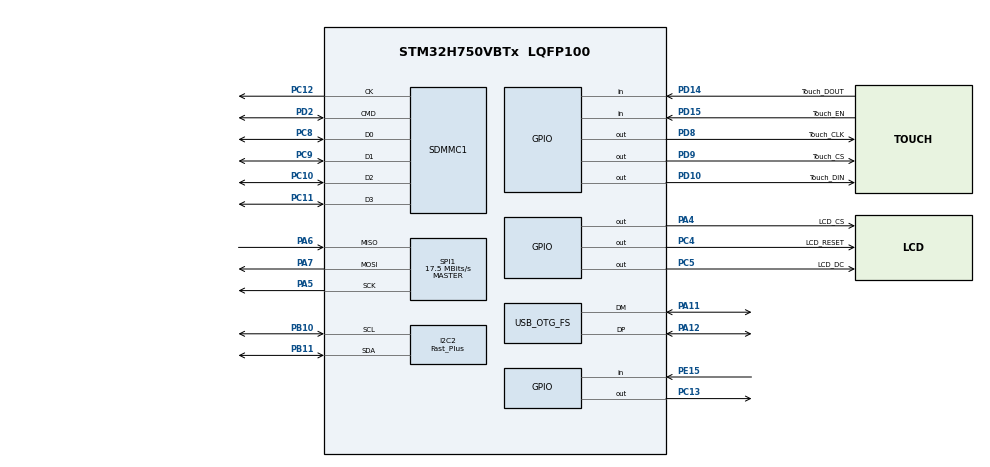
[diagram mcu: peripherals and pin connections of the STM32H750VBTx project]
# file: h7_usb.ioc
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FATFS.BSP.number=1
FATFS0.BSP.STBoard=false
FATFS0.BSP.api=Unknown
FATFS0.BSP.i2caddr=0
FATFS0.BSP.instance=PE15
FATFS0.BSP.ip=GPIO
FATFS0.BSP.mode=Input
FATFS0.BSP.name=Detect_SDIO
FATFS0.BSP.solution=PE15
I2C2.I2C_Speed_Mode=I2C_Fast_Plus
I2C2.Speed=1000
I2C2.Timing=0x0050174F
Mcu.Family=STM32H7
Mcu.Name=STM32H750VBTx
Mcu.Package=LQFP100
NVIC.OTG_FS_IRQn=true\:0\:0\:false\:false\:true\:false\:true
NVIC.PriorityGroup=NVIC_PRIORITYGROUP_4
NVIC.TIM2_IRQn=true\:0\:0\:false\:false\:true\:true\:true
PA10.Signal=USART1_RX
PA11.Mode=Device_Only
PA11.Signal=USB_OTG_FS_DM
PA12.Mode=Device_Only
PA12.Signal=USB_OTG_FS_DP
PA13\ (JTMS/SWDIO).Mode=JTAG_4_pins
PA13\ (JTMS/SWDIO).Signal=DEBUG_JTMS-SWDIO
PA14\ (JTCK/SWCLK).Mode=JTAG_4_pins
PA14\ (JTCK/SWCLK).Signal=DEBUG_JTCK-SWCLK
PA15\ (JTDI).Mode=JTAG_4_pins
PA15\ (JTDI).Signal=DEBUG_JTDI
PA4.GPIO_Label=LCD_CS
PA4.GPIO_Speed=GPIO_SPEED_FREQ_VERY_HIGH
PA4.Signal=GPIO_Output
PA5.Mode=Full_Duplex_Master
PA5.Signal=SPI1_SCK
PA6.Mode=Full_Duplex_Master
PA6.Signal=SPI1_MISO
PA7.Mode=Full_Duplex_Master
PA7.Signal=SPI1_MOSI
PA9.Signal=USART1_TX
PB10.Mode=I2C
PB10.Signal=I2C2_SCL
PB11.Mode=I2C
PB11.Signal=I2C2_SDA
PB3\ (JTDO/TRACESWO).Mode=JTAG_4_pins
PB3\ (JTDO/TRACESWO).Signal=DEBUG_JTDO-SWO
PC10.Mode=SD_4_bits_Wide_bus
PC10.Signal=SDMMC1_D2
PC11.Mode=SD_4_bits_Wide_bus
PC11.Signal=SDMMC1_D3
PC12.Mode=SD_4_bits_Wide_bus
PC12.Signal=SDMMC1_CK
PC13.Signal=GPIO_Output
PC4.GPIO_Label=LCD_RESET
PC4.GPIO_Speed=GPIO_SPEED_FREQ_VERY_HIGH
PC4.Signal=GPIO_Output
PC5.GPIO_Label=LCD_DC
PC5.GPIO_Speed=GPIO_SPEED_FREQ_VERY_HIGH
PC5.Signal=GPIO_Output
PC8.Mode=SD_4_bits_Wide_bus
PC8.Signal=SDMMC1_D0
PC9.Mode=SD_4_bits_Wide_bus
PC9.Signal=SDMMC1_D1
PD10.GPIO_Label=Touch_DIN
PD10.GPIO_Speed=GPIO_SPEED_FREQ_HIGH
PD10.Signal=GPIO_Output
PD14.GPIO_Label=Touch_DOUT
PD14.GPIO_PuPd=GPIO_PULLUP
PD14.Signal=GPIO_Input
PD15.GPIO_Label=Touch_EN
PD15.GPIO_PuPd=GPIO_PULLUP
PD15.Signal=GPIO_Input
PD2.Mode=SD_4_bits_Wide_bus
PD2.Signal=SDMMC1_CMD
PD8.GPIO_Label=Touch_CLK
PD8.GPIO_Speed=GPIO_SPEED_FREQ_HIGH
PD8.Signal=GPIO_Output
PD9.GPIO_Label=Touch_CS
PD9.GPIO_Speed=GPIO_SPEED_FREQ_HIGH
PD9.Signal=GPIO_Output
PE15.GPIO_PuPd=GPIO_PULLDOWN
PE15.Signal=GPIO_Input
PH0-OSC_IN\ (PH0).Mode=HSE-External-Oscillator
PH0-OSC_IN\ (PH0).Signal=RCC_OSC_IN
PH1-OSC_OUT\ (PH1).Mode=HSE-External-Oscillator
PH1-OSC_OUT\ (PH1).Signal=RCC_OSC_OUT
ProjectManager.HeapSize=0x2200
ProjectManager.StackSize=0x2400
ProjectManager.TargetToolchain=MDK-ARM V5
RCC.ADCFreq_Value=35000000
RCC.APB1Freq_Value=120000000
RCC.APB2Freq_Value=120000000
RCC.APB3Freq_Value=120000000
RCC.APB4Freq_Value=120000000
RCC.CortexFreq_Value=480000000
RCC.D1PPRE=RCC_APB3_DIV2
RCC.D2PPRE1=RCC_APB1_DIV2
RCC.D2PPRE2=RCC_APB2_DIV2
RCC.D3PPRE=RCC_APB4_DIV2
RCC.DIVM1=5
RCC.DIVM2=25
RCC.DIVM3=25
RCC.DIVN1=192
RCC.DIVN2=210
RCC.DIVN3=192
RCC.DIVP2=6
RCC.DIVQ3=4
RCC.DIVR2=5
RCC.DIVR3=6
RCC.HCLKFreq_Value=240000000
RCC.HPRE=RCC_HCLK_DIV2
RCC.HSE_VALUE=25000000
RCC.SDMMC1CLockSelection=RCC_SDMMCCLKSOURCE_PLL2
RCC.SPI123CLockSelection=RCC_SPI123CLKSOURCE_PLL2
RCC.SYSCLKFreq_VALUE=480000000
RCC.SYSCLKSource=RCC_SYSCLKSOURCE_PLLCLK
RCC.USBCLockSelection=RCC_USBCLKSOURCE_PLL3
RCC.USBFreq_Value=48000000
SPI1.CalculateBaudRate=17.5 MBits/s
SPI1.DataSize=SPI_DATASIZE_8BIT
SPI1.Direction=SPI_DIRECTION_2LINES
SPI1.Mode=SPI_MODE_MASTER
SPI1.VirtualType=VM_MASTER
TIM2.Period=1000-1
TIM2.Prescaler=240-1
TIM6.AutoReloadPreload=TIM_AUTORELOAD_PRELOAD_ENABLE
TIM6.Period=65535
TIM6.Prescaler=240-1
USB_DEVICE.CLASS_NAME_FS=CDC
USB_DEVICE.VirtualMode-CDC_FS=Cdc
USB_DEVICE.VirtualModeFS=Cdc_FS
USB_OTG_FS.VirtualMode=Device_Only
VP_FATFS_VS_SDIO.Mode=SDIO
VP_RNG_VS_RNG.Mode=RNG_Activate
VP_TIM2_VS_ClockSourceINT.Mode=Internal
VP_TIM6_VS_ClockSourceINT.Mode=Enable_Timer
VP_USB_DEVICE_VS_USB_DEVICE_CDC_FS.Mode=CDC_FS
board=custom

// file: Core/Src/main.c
/* USER CODE BEGIN Header */
/**
  ******************************************************************************
  * @file           : main.c
  * @brief          : Main program body
  ******************************************************************************
  * @attention
  *
  * <h2><center>&copy; Copyright (c) 2021 STMicroelectronics.
  * All rights reserved.</center></h2>
  *
  * This software component is licensed by ST under Ultimate Liberty license
  * SLA0044, the "License"; You may not use this file except in compliance with
  * the License. You may obtain a copy of the License at:
  *                             www.st.com/SLA0044
  *
  ******************************************************************************
  */
/* USER CODE END Header */
#include "main.h"
#include "fatfs.h"
#include "i2c.h"
#include "rng.h"
#include "sdmmc.h"
#include "spi.h"
#include "tim.h"
#include "usb_device.h"
#include "gpio.h"

/* USER CODE BEGIN Includes */
#include "iic_oled.h"
#include "usbd_cdc_if.h"
#include "bsp_file.h"
#include "spi_lcd.h"
#include "bsp_user.h"
#include "lv_conf.h"
#include "lv_port_disp.h"
#include "lvgl.h"
/* USER CODE END Includes */

/* USER CODE BEGIN PTD */
extern FATFS SDFatFS; /* File system object for SD logical drive */
/* USER CODE END PTD */

void SystemClock_Config(void);

int main(void)
{
  /* USER CODE BEGIN 1 */
    SCB_EnableICache();
    SCB_EnableDCache();
    int cnt = 0;
    long old_tick;
  /* USER CODE END 1 */

  /* MCU Configuration--------------------------------------------------------*/

  /* Reset of all peripherals, Initializes the Flash interface and the Systick. */
  HAL_Init();

  /* Configure the system clock */
  SystemClock_Config();

  /* Initialize all configured peripherals */
  MX_GPIO_Init();
  MX_SDMMC1_SD_Init();
  MX_FATFS_Init();
  MX_USB_DEVICE_Init();
  MX_I2C2_Init();
  MX_SPI1_Init();
  MX_TIM2_Init();
  MX_RNG_Init();
  MX_TIM6_Init();
  /* USER CODE BEGIN 2 */
    bsp_init();
  /* USER CODE END 2 */

  /* Infinite loop */
    while (1)
    {

    /* USER CODE BEGIN 3 */
        //show_rng();
        //		cnt++;
        //		LCD_Clear(RED);
        //		LCD_Clear(BLACK);
        //		if(cnt==10)
        //		{
        //			usb_printf("%d\r\n",HAL_GetTick()-old_tick);
        //			old_tick=HAL_GetTick();
        //			cnt=0;
        //		}
    }
  /* USER CODE END 3 */
}

void SystemClock_Config(void)
{
  RCC_OscInitTypeDef RCC_OscInitStruct = {0};
  RCC_ClkInitTypeDef RCC_ClkInitStruct = {0};
  RCC_PeriphCLKInitTypeDef PeriphClkInitStruct = {0};

  /** Supply configuration update enable
  */
  HAL_PWREx_ConfigSupply(PWR_LDO_SUPPLY);
  /** Configure the main internal regulator output voltage
  */
  __HAL_PWR_VOLTAGESCALING_CONFIG(PWR_REGULATOR_VOLTAGE_SCALE0);

  while(!__HAL_PWR_GET_FLAG(PWR_FLAG_VOSRDY)) {}
  /** Macro to configure the PLL clock source
  */
  __HAL_RCC_PLL_PLLSOURCE_CONFIG(RCC_PLLSOURCE_HSE);
  /** Initializes the RCC Oscillators according to the specified parameters
  * in the RCC_OscInitTypeDef structure.
  */
  RCC_OscInitStruct.OscillatorType = RCC_OSCILLATORTYPE_HSI48|RCC_OSCILLATORTYPE_HSE;
  RCC_OscInitStruct.HSEState = RCC_HSE_ON;
  RCC_OscInitStruct.HSI48State = RCC_HSI48_ON;
  RCC_OscInitStruct.PLL.PLLState = RCC_PLL_ON;
  RCC_OscInitStruct.PLL.PLLSource = RCC_PLLSOURCE_HSE;
  RCC_OscInitStruct.PLL.PLLM = 5;
  RCC_OscInitStruct.PLL.PLLN = 192;
  RCC_OscInitStruct.PLL.PLLP = 2;
  RCC_OscInitStruct.PLL.PLLQ = 2;
  RCC_OscInitStruct.PLL.PLLR = 2;
  RCC_OscInitStruct.PLL.PLLRGE = RCC_PLL1VCIRANGE_2;
  RCC_OscInitStruct.PLL.PLLVCOSEL = RCC_PLL1VCOWIDE;
  RCC_OscInitStruct.PLL.PLLFRACN = 0;
  if (HAL_RCC_OscConfig(&RCC_OscInitStruct) != HAL_OK)
  {
    Error_Handler();
  }
  /** Initializes the CPU, AHB and APB buses clocks
  */
  RCC_ClkInitStruct.ClockType = RCC_CLOCKTYPE_HCLK|RCC_CLOCKTYPE_SYSCLK
                              |RCC_CLOCKTYPE_PCLK1|RCC_CLOCKTYPE_PCLK2
                              |RCC_CLOCKTYPE_D3PCLK1|RCC_CLOCKTYPE_D1PCLK1;
  RCC_ClkInitStruct.SYSCLKSource = RCC_SYSCLKSOURCE_PLLCLK;
  RCC_ClkInitStruct.SYSCLKDivider = RCC_SYSCLK_DIV1;
  RCC_ClkInitStruct.AHBCLKDivider = RCC_HCLK_DIV2;
  RCC_ClkInitStruct.APB3CLKDivider = RCC_APB3_DIV2;
  RCC_ClkInitStruct.APB1CLKDivider = RCC_APB1_DIV2;
  RCC_ClkInitStruct.APB2CLKDivider = RCC_APB2_DIV2;
  RCC_ClkInitStruct.APB4CLKDivider = RCC_APB4_DIV2;

  if (HAL_RCC_ClockConfig(&RCC_ClkInitStruct, FLASH_LATENCY_4) != HAL_OK)
  {
    Error_Handler();
  }
  PeriphClkInitStruct.PeriphClockSelection = RCC_PERIPHCLK_RNG|RCC_PERIPHCLK_SPI1
                              |RCC_PERIPHCLK_SDMMC|RCC_PERIPHCLK_I2C2
                              |RCC_PERIPHCLK_USB;
  PeriphClkInitStruct.PLL2.PLL2M = 25;
  PeriphClkInitStruct.PLL2.PLL2N = 210;
  PeriphClkInitStruct.PLL2.PLL2P = 6;
  PeriphClkInitStruct.PLL2.PLL2Q = 2;
  PeriphClkInitStruct.PLL2.PLL2R = 5;
  PeriphClkInitStruct.PLL2.PLL2RGE = RCC_PLL2VCIRANGE_0;
  PeriphClkInitStruct.PLL2.PLL2VCOSEL = RCC_PLL2VCOWIDE;
  PeriphClkInitStruct.PLL2.PLL2FRACN = 0;
  PeriphClkInitStruct.PLL3.PLL3M = 25;
  PeriphClkInitStruct.PLL3.PLL3N = 192;
  PeriphClkInitStruct.PLL3.PLL3P = 2;
  PeriphClkInitStruct.PLL3.PLL3Q = 4;
  PeriphClkInitStruct.PLL3.PLL3R = 6;
  PeriphClkInitStruct.PLL3.PLL3RGE = RCC_PLL3VCIRANGE_0;
  PeriphClkInitStruct.PLL3.PLL3VCOSEL = RCC_PLL3VCOWIDE;
  PeriphClkInitStruct.PLL3.PLL3FRACN = 0;
  PeriphClkInitStruct.SdmmcClockSelection = RCC_SDMMCCLKSOURCE_PLL2;
  PeriphClkInitStruct.Spi123ClockSelection = RCC_SPI123CLKSOURCE_PLL2;
  PeriphClkInitStruct.RngClockSelection = RCC_RNGCLKSOURCE_HSI48;
  PeriphClkInitStruct.I2c123ClockSelection = RCC_I2C123CLKSOURCE_D2PCLK1;
  PeriphClkInitStruct.UsbClockSelection = RCC_USBCLKSOURCE_PLL3;
  if (HAL_RCCEx_PeriphCLKConfig(&PeriphClkInitStruct) != HAL_OK)
  {
    Error_Handler();
  }
  /** Enable USB Voltage detector
  */
  HAL_PWREx_EnableUSBVoltageDetector();
}

void Error_Handler(void)
{
    __disable_irq();
    while (1)
    {
    }
}

/************************ (C) COPYRIGHT STMicroelectronics *****END OF FILE****/
